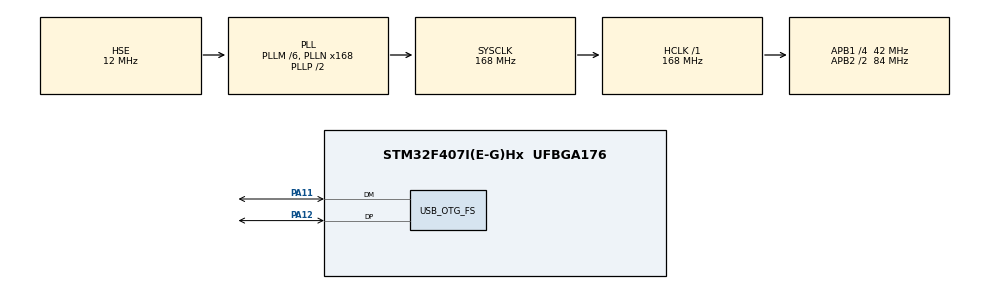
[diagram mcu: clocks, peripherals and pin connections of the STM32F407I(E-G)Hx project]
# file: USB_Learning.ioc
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FREERTOS.MEMORY_ALLOCATION=0
FREERTOS.Tasks01=DebugTask,8,1024,StartDebugTask,As weak,NULL,Dynamic,NULL,NULL;USBTask,24,128,StartUSBTask,As external,NULL,Dynamic,NULL,NULL
FREERTOS.configTOTAL_HEAP_SIZE=64000
FREERTOS.configUSE_NEWLIB_REENTRANT=1
Mcu.Family=STM32F4
Mcu.Name=STM32F407I(E-G)Hx
Mcu.Package=UFBGA176
NVIC.OTG_FS_IRQn=true\:5\:0\:false\:false\:true\:true\:true\:true\:true
NVIC.PriorityGroup=NVIC_PRIORITYGROUP_4
PA11.Mode=Device_Only
PA11.Signal=USB_OTG_FS_DM
PA12.Mode=Device_Only
PA12.Signal=USB_OTG_FS_DP
PH0-OSC_IN.Mode=HSE-External-Oscillator
PH0-OSC_IN.Signal=RCC_OSC_IN
PH1-OSC_OUT.Mode=HSE-External-Oscillator
PH1-OSC_OUT.Signal=RCC_OSC_OUT
ProjectManager.HeapSize=0x200
ProjectManager.StackSize=0x400
ProjectManager.TargetToolchain=CMake
RCC.48MHZClocksFreq_Value=48000000
RCC.AHBFreq_Value=168000000
RCC.APB1CLKDivider=RCC_HCLK_DIV4
RCC.APB1Freq_Value=42000000
RCC.APB1TimFreq_Value=84000000
RCC.APB2CLKDivider=RCC_HCLK_DIV2
RCC.APB2Freq_Value=84000000
RCC.APB2TimFreq_Value=168000000
RCC.CortexFreq_Value=168000000
RCC.HCLKFreq_Value=168000000
RCC.HSE_VALUE=12000000
RCC.HSI_VALUE=16000000
RCC.LSE_VALUE=32768
RCC.PLLM=6
RCC.PLLN=168
RCC.PLLQ=7
RCC.SYSCLKFreq_VALUE=168000000
RCC.SYSCLKSource=RCC_SYSCLKSOURCE_PLLCLK
RCC.VCOOutputFreq_Value=336000000
USB_OTG_FS.VirtualMode=Device_Only
VP_FREERTOS_VS_CMSIS_V2.Mode=CMSIS_V2
board=custom

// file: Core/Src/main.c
/* USER CODE BEGIN Header */
/**
  ******************************************************************************
  * @file           : main.c
  * @brief          : Main program body
  ******************************************************************************
  * @attention
  *
  * Copyright (c) 2025 STMicroelectronics.
  * All rights reserved.
  *
  * This software is licensed under terms that can be found in the LICENSE file
  * in the root directory of this software component.
  * If no LICENSE file comes with this software, it is provided AS-IS.
  *
  ******************************************************************************
  */
/* USER CODE END Header */
#include "main.h"
#include "cmsis_os.h"
#include "usb_otg.h"
#include "gpio.h"

/* USER CODE BEGIN Includes */
#include "task_public.h"
/* USER CODE END Includes */

void SystemClock_Config(void);
void MX_FREERTOS_Init(void);

int main(void)
{

  /* MCU Configuration--------------------------------------------------------*/

  /* Reset of all peripherals, Initializes the Flash interface and the Systick. */
  HAL_Init();

  /* Configure the system clock */
  SystemClock_Config();

  /* Initialize all configured peripherals */
  MX_GPIO_Init();
  MX_USB_OTG_FS_PCD_Init();

  /* Init scheduler */
  osKernelInitialize();

  /* Call init function for freertos objects (in cmsis_os2.c) */
  MX_FREERTOS_Init();

  /* Start scheduler */
  osKernelStart();

  /* We should never get here as control is now taken by the scheduler */

  /* Infinite loop */
  while (1)
  {

  }
}

void SystemClock_Config(void)
{
  RCC_OscInitTypeDef RCC_OscInitStruct = {0};
  RCC_ClkInitTypeDef RCC_ClkInitStruct = {0};

  /** Configure the main internal regulator output voltage
  */
  __HAL_RCC_PWR_CLK_ENABLE();
  __HAL_PWR_VOLTAGESCALING_CONFIG(PWR_REGULATOR_VOLTAGE_SCALE1);

  /** Initializes the RCC Oscillators according to the specified parameters
  * in the RCC_OscInitTypeDef structure.
  */
  RCC_OscInitStruct.OscillatorType = RCC_OSCILLATORTYPE_HSE;
  RCC_OscInitStruct.HSEState = RCC_HSE_ON;
  RCC_OscInitStruct.PLL.PLLState = RCC_PLL_ON;
  RCC_OscInitStruct.PLL.PLLSource = RCC_PLLSOURCE_HSE;
  RCC_OscInitStruct.PLL.PLLM = 6;
  RCC_OscInitStruct.PLL.PLLN = 168;
  RCC_OscInitStruct.PLL.PLLP = RCC_PLLP_DIV2;
  RCC_OscInitStruct.PLL.PLLQ = 7;
  if (HAL_RCC_OscConfig(&RCC_OscInitStruct) != HAL_OK)
  {
    Error_Handler();
  }

  /** Initializes the CPU, AHB and APB buses clocks
  */
  RCC_ClkInitStruct.ClockType = RCC_CLOCKTYPE_HCLK|RCC_CLOCKTYPE_SYSCLK
                              |RCC_CLOCKTYPE_PCLK1|RCC_CLOCKTYPE_PCLK2;
  RCC_ClkInitStruct.SYSCLKSource = RCC_SYSCLKSOURCE_PLLCLK;
  RCC_ClkInitStruct.AHBCLKDivider = RCC_SYSCLK_DIV1;
  RCC_ClkInitStruct.APB1CLKDivider = RCC_HCLK_DIV4;
  RCC_ClkInitStruct.APB2CLKDivider = RCC_HCLK_DIV2;

  if (HAL_RCC_ClockConfig(&RCC_ClkInitStruct, FLASH_LATENCY_5) != HAL_OK)
  {
    Error_Handler();
  }
}

void Error_Handler(void)
{
  __disable_irq();
  while (1)
  {
  }
}

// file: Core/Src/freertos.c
/* USER CODE BEGIN Header */
/**
  ******************************************************************************
  * File Name          : freertos.c
  * Description        : Code for freertos applications
  ******************************************************************************
  * @attention
  *
  * Copyright (c) 2025 STMicroelectronics.
  * All rights reserved.
  *
  * This software is licensed under terms that can be found in the LICENSE file
  * in the root directory of this software component.
  * If no LICENSE file comes with this software, it is provided AS-IS.
  *
  ******************************************************************************
  */
/* USER CODE END Header */

#include "FreeRTOS.h"
#include "task.h"
#include "main.h"
#include "cmsis_os.h"

/* Definitions for DebugTask */
osThreadId_t DebugTaskHandle;
const osThreadAttr_t DebugTask_attributes = {
  .name = "DebugTask",
  .stack_size = 1024 * 4,
  .priority = (osPriority_t) osPriorityLow,
};
/* Definitions for USBTask */
osThreadId_t USBTaskHandle;
const osThreadAttr_t USBTask_attributes = {
  .name = "USBTask",
  .stack_size = 128 * 4,
  .priority = (osPriority_t) osPriorityNormal,
};

void StartDebugTask(void *argument);
extern void StartUSBTask(void *argument);

void MX_FREERTOS_Init(void); /* (MISRA C 2004 rule 8.1) */

void MX_FREERTOS_Init(void) {

  /* Create the thread(s) */
  /* creation of DebugTask */
  DebugTaskHandle = osThreadNew(StartDebugTask, NULL, &DebugTask_attributes);

  /* creation of USBTask */
  USBTaskHandle = osThreadNew(StartUSBTask, NULL, &USBTask_attributes);

}

__weak void StartDebugTask(void *argument)
{
  for(;;)
  {
    osDelay(1);
  }
}
